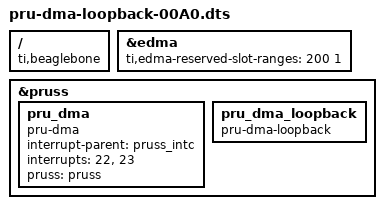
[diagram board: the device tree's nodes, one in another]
/dts-v1/;
/plugin/;

/ {
	compatible = "ti,beaglebone", "ti,beaglebone-black", "ti,beaglebone-green";

	fragment@0 {
		target = <&edma>;

		__overlay__ {
			/* Reserve PaRAM slot for PRU use -
			 * won't be used in linux transfers.
			 * 200 is slot number and 1 means we
			 * only want one slot.
			 */
			ti,edma-reserved-slot-ranges = <200 1>;
		};
	};

	fragment@1 {
		target = <&pruss>;
		__overlay__ {
			pru_dma {
				compatible = "pru-dma";
				interrupt-parent = <&pruss_intc>;
				interrupts = <22>, <23>;
				interrupt-names = "irq_from_pru", "irq_to_pru";
				pruss = <&pruss>;
			};

			pru_dma_loopback {
				compatible = "pru-dma-loopback";
			};
		};
	};
};
